# hercules_arm_m3_nvic_trm_r1p1 register map
Vendor: Texas Instruments
Peripheral module from a debugger description file (folder hercules).
Registers are 32-bit, read-write, no defined reset value unless marked. A register's access mark holds for its fields unless they carry their own. Offsets are as the file gives them; lines under a group give offsets from that group; [hi:lo] are bit positions; {n}, {i} and the like mark numbered series; 'fields as' and 'values as' point back to an identical list; <NAME> marks a mode.

## NVIC — Nested Vector Interrupt Controller
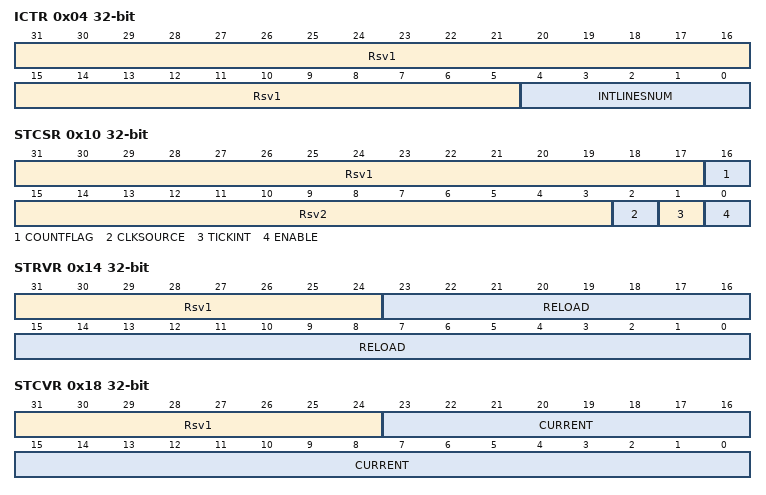
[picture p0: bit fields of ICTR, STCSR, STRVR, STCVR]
0x04 ICTR ro — Interrupt Control Type Register
  [31:5] Rsv1 — Reserved
  [4:0] INTLINESNUM — (N-1)/32 Where N=Number of Interrupt Lines. ex 0=1-32, 1=33-64, etc.
0x10 STCSR access per field — SysTick Control and Status Register
  [31:17] Rsv1 ro — Reserved
  [16] COUNTFLAG rw — Counter Reached 0: 0=No, 1=Yes, Read-Clear
  [15:3] Rsv2 ro — Reserved
  [2] CLKSOURCE rw — Reference Clock Source 0=core clock, 1=external clock
  [1] TICKINT rw — Counter Reaching 0 Pends SysTick Handler 0=No, 1=Yes
  [0] ENABLE rw — Counter Enable: 0=Disabled, 1=Multishot
0x14 STRVR access per field — SysTick Reload Value Register
  [31:24] Rsv1 ro — Reserved
  [23:0] RELOAD rw — Value Loaded by SysTick Counter when Reaching 0
0x18 STCVR access per field — SysTick Current Value Register
  [31:24] Rsv1 ro — Reserved
  [23:0] CURRENT rw — Currrent SysTick Counter Value
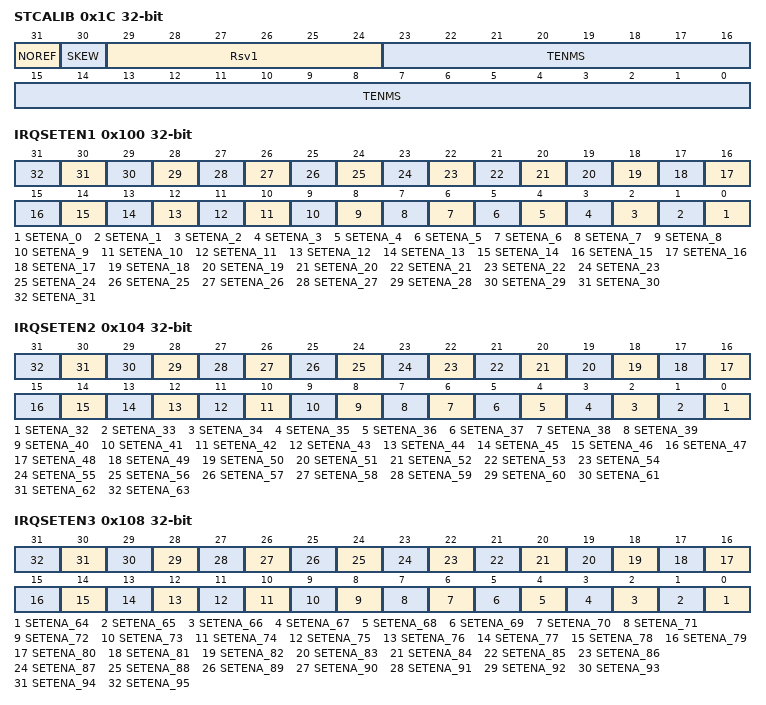
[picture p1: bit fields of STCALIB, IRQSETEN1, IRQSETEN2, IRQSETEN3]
0x1C STCALIB ro — SysTick Calibration Value Register
  [31] NOREF — 1 = Reference Clock Not Provided
  [30] SKEW — 1 = Calibration Value Not Exactly 10ms
  [29:24] Rsv1 — Reserved
  [23:0] TENMS — Reload Value to Generate 10ms SysTick
0x100 IRQSETEN1 — Interrupt 0-31 Set Enable Register
  [n] SETENA_{n} (n=0..31) — Writes: 1 Enables Interrupt, 0 No Effect. Read 1=Interrupt Enabled
0x104 IRQSETEN2 — Interrupt 32-63 Set Enable Register
  [n-32] SETENA_{n} (n=32..63) — Writes: 1 Enables Interrupt, 0 No Effect. Read 1=Interrupt Enabled
0x108 IRQSETEN3 — Interrupt 64-95 Set Enable Register
  [n-64] SETENA_{n} (n=64..95) — Writes: 1 Enables Interrupt, 0 No Effect. Read 1=Interrupt Enabled
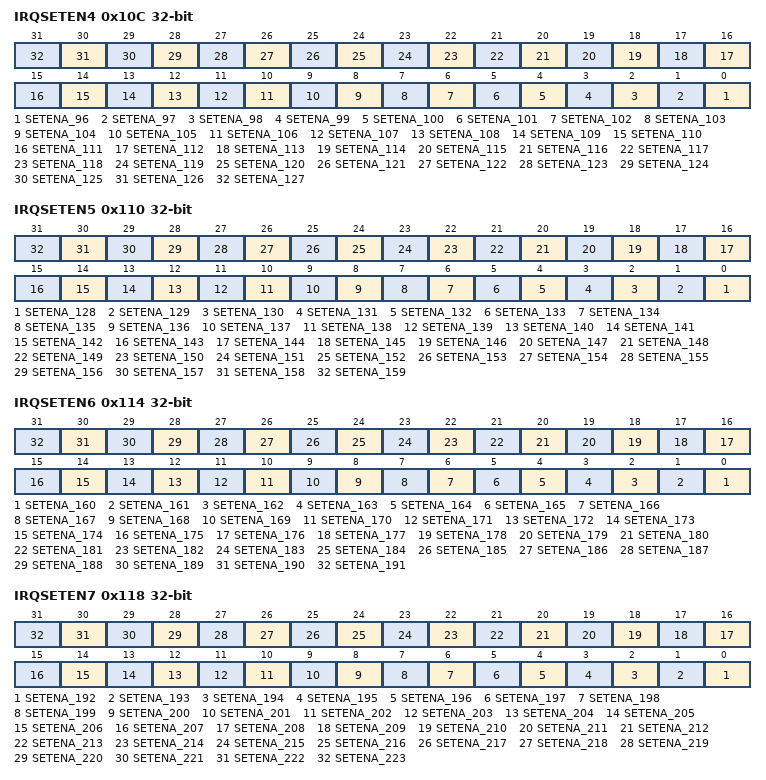
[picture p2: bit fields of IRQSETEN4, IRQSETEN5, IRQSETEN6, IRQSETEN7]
0x10C IRQSETEN4 — Interrupt 96-127 Set Enable Register
  [n-96] SETENA_{n} (n=96..127) — Writes: 1 Enables Interrupt, 0 No Effect. Read 1=Interrupt Enabled
0x110 IRQSETEN5 — Interrupt 128-159 Set Enable Register
  [n-128] SETENA_{n} (n=128..159) — Writes: 1 Enables Interrupt, 0 No Effect. Read 1=Interrupt Enabled
0x114 IRQSETEN6 — Interrupt 160-191 Set Enable Register
  [n-160] SETENA_{n} (n=160..191) — Writes: 1 Enables Interrupt, 0 No Effect. Read 1=Interrupt Enabled
0x118 IRQSETEN7 — Interrupt 192-223 Set Enable Register
  [n-192] SETENA_{n} (n=192..223) — Writes: 1 Enables Interrupt, 0 No Effect. Read 1=Interrupt Enabled
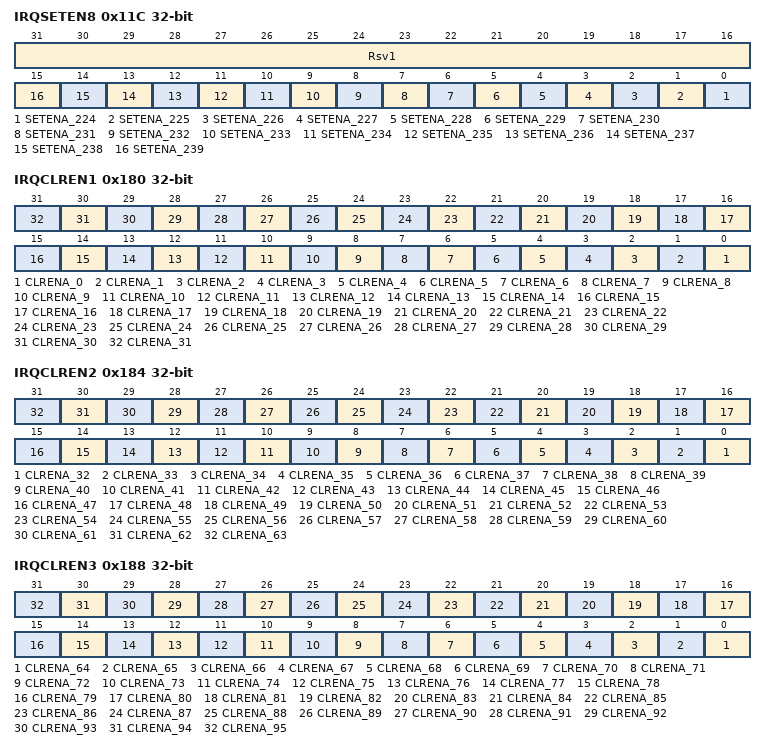
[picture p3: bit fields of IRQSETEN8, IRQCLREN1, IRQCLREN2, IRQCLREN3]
0x11C IRQSETEN8 access per field — Interrupt 224-239 Set Enable Register
  [31:16] Rsv1 ro — Reserved
  [n-224] SETENA_{n} rw (n=224..239) — Writes: 1 Enables Interrupt, 0 No Effect. Read 1=Interrupt Enabled
0x180 IRQCLREN1 — Interrupt 0-31 Clear Enable Register
  [n] CLRENA_{n} (n=0..31) — Writes: 1 Disables Interrupt, 0 No Effect. Read 1=Interrupt Enabled
0x184 IRQCLREN2 — Interrupt 32-63 Clear Enable Register
  [n-32] CLRENA_{n} (n=32..63) — Writes: 1 Disables Interrupt, 0 No Effect. Read 1=Interrupt Enabled
0x188 IRQCLREN3 — Interrupt 64-95 Clear Enable Register
  [n-64] CLRENA_{n} (n=64..95) — Writes: 1 Disables Interrupt, 0 No Effect. Read 1=Interrupt Enabled
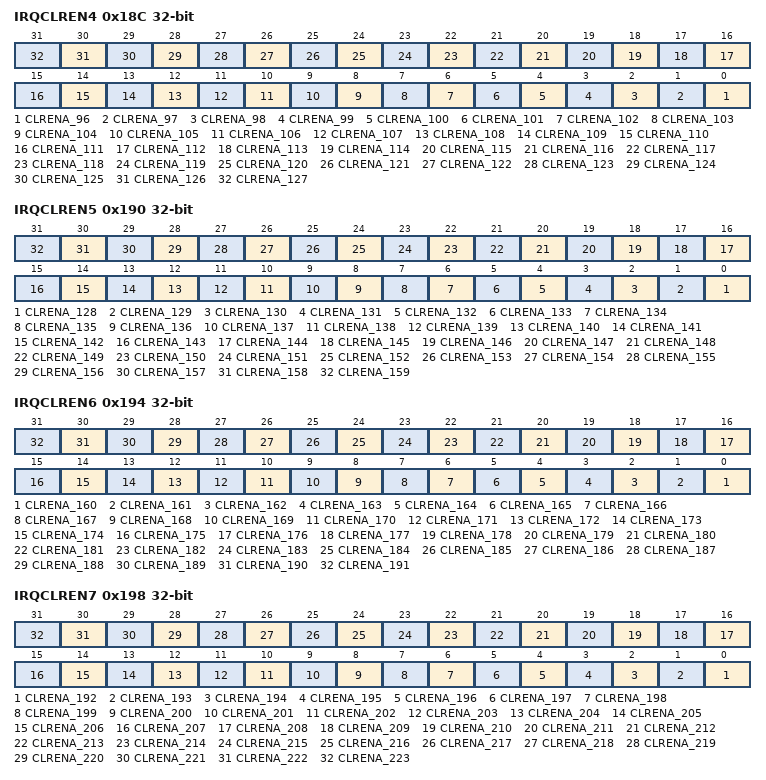
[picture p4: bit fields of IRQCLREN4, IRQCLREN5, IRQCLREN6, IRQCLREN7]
0x18C IRQCLREN4 — Interrupt 96-127 Clear Enable Register
  [n-96] CLRENA_{n} (n=96..127) — Writes: 1 Disables Interrupt, 0 No Effect. Read 1=Interrupt Enabled
0x190 IRQCLREN5 — Interrupt 128-159 Clear Enable Register
  [n-128] CLRENA_{n} (n=128..159) — Writes: 1 Disables Interrupt, 0 No Effect. Read 1=Interrupt Enabled
0x194 IRQCLREN6 — Interrupt 160-191 Clear Enable Register
  [n-160] CLRENA_{n} (n=160..191) — Writes: 1 Disables Interrupt, 0 No Effect. Read 1=Interrupt Enabled
0x198 IRQCLREN7 — Interrupt 192-223 Clear Enable Register
  [n-192] CLRENA_{n} (n=192..223) — Writes: 1 Disables Interrupt, 0 No Effect. Read 1=Interrupt Enabled
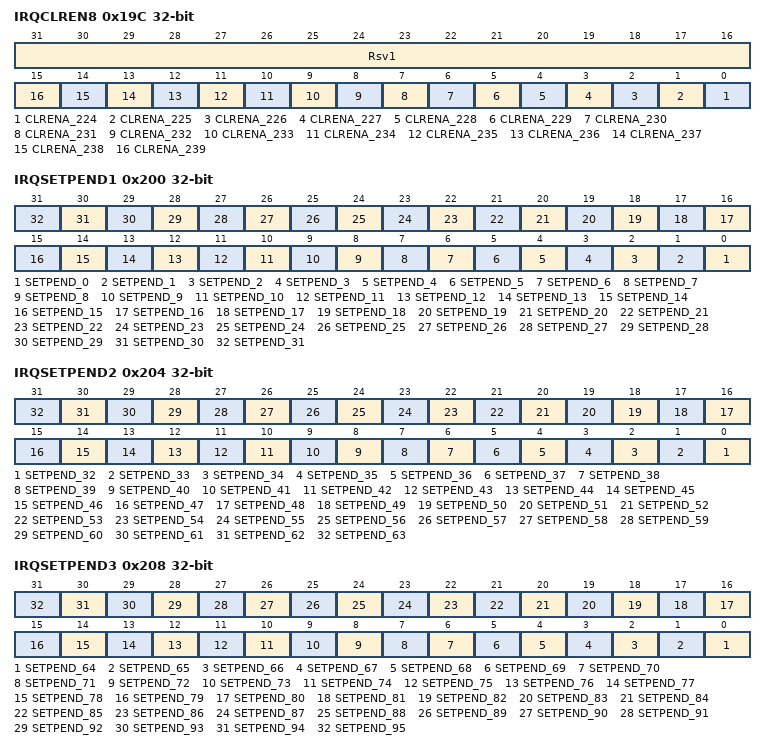
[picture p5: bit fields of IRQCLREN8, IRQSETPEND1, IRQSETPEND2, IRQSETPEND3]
0x19C IRQCLREN8 access per field — Interrupt 224-239 Clear Enable Register
  [31:16] Rsv1 ro — Reserved
  [n-224] CLRENA_{n} rw (n=224..239) — Writes: 1 Disables Interrupt, 0 No Effect. Read 1=Interrupt Enabled
0x200 IRQSETPEND1 — Interrupt 0-31 Set Pending Register
  [n] SETPEND_{n} (n=0..31) — Writes: 1 Pends Interrupt, 0 No Effect. Read 1=Interrupt Pending
0x204 IRQSETPEND2 — Interrupt 32-63 Set Pending Register
  [n-32] SETPEND_{n} (n=32..63) — Writes: 1 Pends Interrupt, 0 No Effect. Read 1=Interrupt Pending
0x208 IRQSETPEND3 — Interrupt 64-95 Set Pending Register
  [n-64] SETPEND_{n} (n=64..95) — Writes: 1 Pends Interrupt, 0 No Effect. Read 1=Interrupt Pending
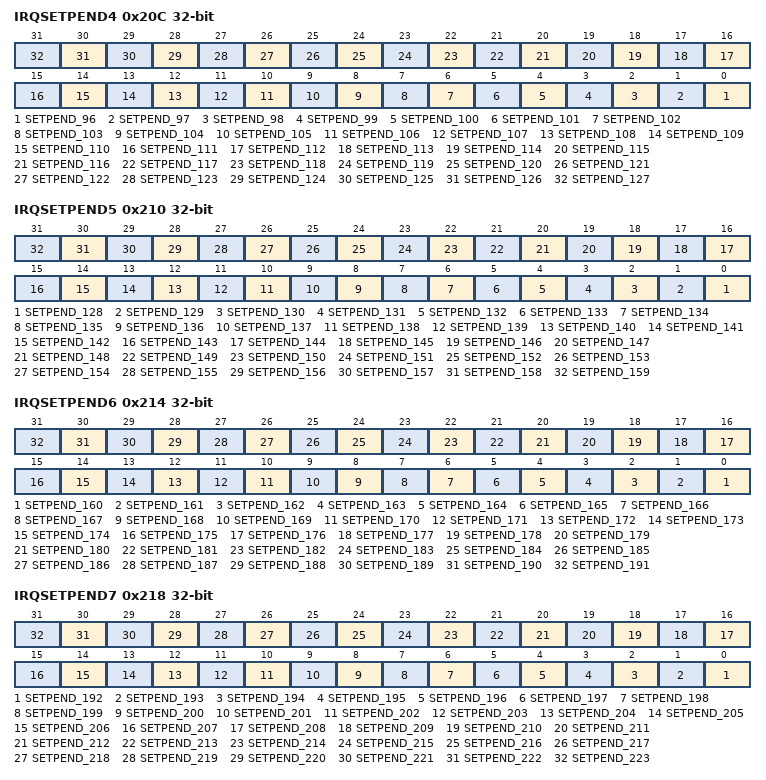
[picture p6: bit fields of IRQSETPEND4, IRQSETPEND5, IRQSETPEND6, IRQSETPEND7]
0x20C IRQSETPEND4 — Interrupt 96-127 Set Pending Register
  [n-96] SETPEND_{n} (n=96..127) — Writes: 1 Pends Interrupt, 0 No Effect. Read 1=Interrupt Pending
0x210 IRQSETPEND5 — Interrupt 128-159 Set Pending Register
  [n-128] SETPEND_{n} (n=128..159) — Writes: 1 Pends Interrupt, 0 No Effect. Read 1=Interrupt Pending
0x214 IRQSETPEND6 — Interrupt 160-191 Set Pending Register
  [n-160] SETPEND_{n} (n=160..191) — Writes: 1 Pends Interrupt, 0 No Effect. Read 1=Interrupt Pending
0x218 IRQSETPEND7 — Interrupt 192-223 Set Pending Register
  [n-192] SETPEND_{n} (n=192..223) — Writes: 1 Pends Interrupt, 0 No Effect. Read 1=Interrupt Pending
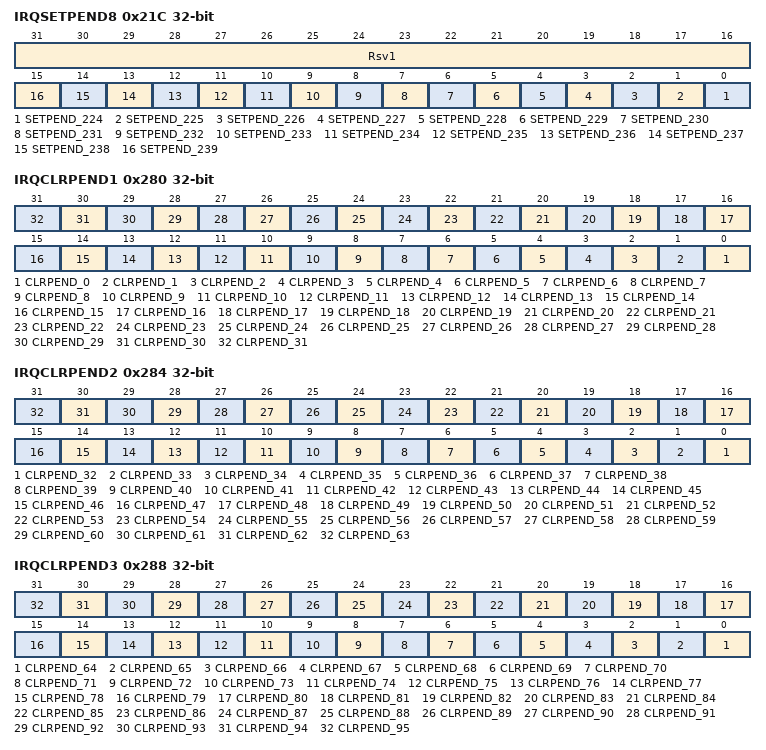
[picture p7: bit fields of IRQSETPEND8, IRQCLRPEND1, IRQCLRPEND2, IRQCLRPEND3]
0x21C IRQSETPEND8 access per field — Interrupt 224-239 Set Pending Register
  [31:16] Rsv1 ro — Reserved
  [n-224] SETPEND_{n} rw (n=224..239) — Writes: 1 Pends Interrupt, 0 No Effect. Read 1=Interrupt Pending
0x280 IRQCLRPEND1 — Interrupt 0-31 Clear Pending Register
  [n] CLRPEND_{n} (n=0..31) — Writes: 1 Clears Pending Interrupt, 0 No Effect. Read 1=Interrupt Pending
0x284 IRQCLRPEND2 — Interrupt 32-63 Clear Pending Register
  [n-32] CLRPEND_{n} (n=32..63) — Writes: 1 Clears Pending Interrupt, 0 No Effect. Read 1=Interrupt Pending
0x288 IRQCLRPEND3 — Interrupt 64-95 Clear Pending Register
  [n-64] CLRPEND_{n} (n=64..95) — Writes: 1 Clears Pending Interrupt, 0 No Effect. Read 1=Interrupt Pending
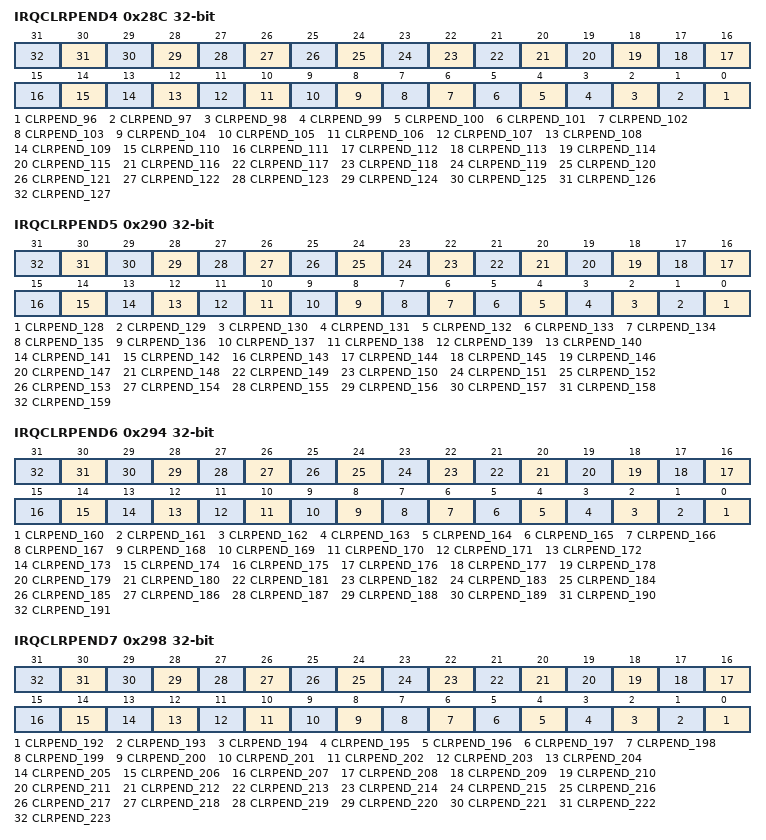
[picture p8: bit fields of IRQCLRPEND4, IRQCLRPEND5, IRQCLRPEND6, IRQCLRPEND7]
0x28C IRQCLRPEND4 — Interrupt 96-127 Clear Pending Register
  [n-96] CLRPEND_{n} (n=96..127) — Writes: 1 Clears Pending Interrupt, 0 No Effect. Read 1=Interrupt Pending
0x290 IRQCLRPEND5 — Interrupt 128-159 Clear Pending Register
  [n-128] CLRPEND_{n} (n=128..159) — Writes: 1 Clears Pending Interrupt, 0 No Effect. Read 1=Interrupt Pending
0x294 IRQCLRPEND6 — Interrupt 160-191 Clear Pending Register
  [n-160] CLRPEND_{n} (n=160..191) — Writes: 1 Clears Pending Interrupt, 0 No Effect. Read 1=Interrupt Pending
0x298 IRQCLRPEND7 — Interrupt 192-223 Clear Pending Register
  [n-192] CLRPEND_{n} (n=192..223) — Writes: 1 Clears Pending Interrupt, 0 No Effect. Read 1=Interrupt Pending
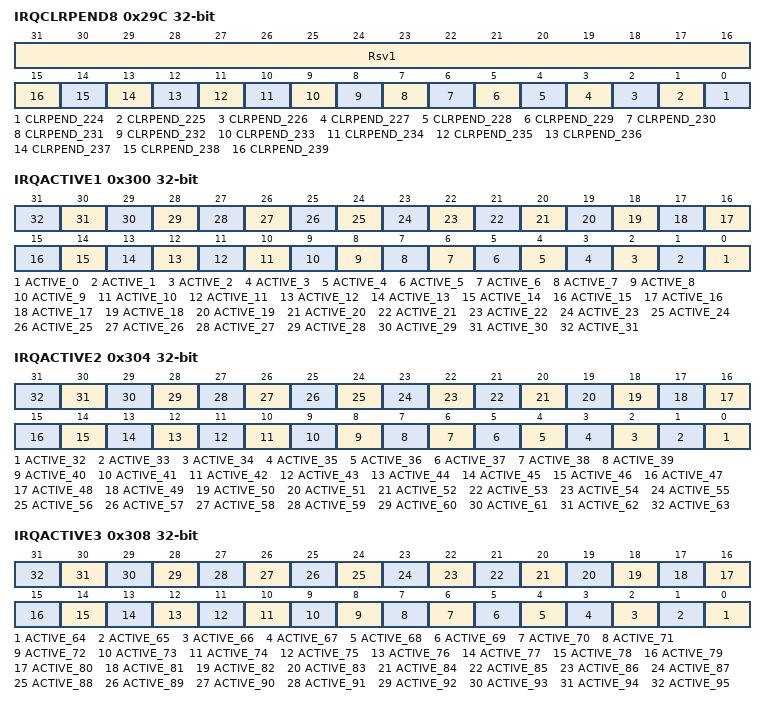
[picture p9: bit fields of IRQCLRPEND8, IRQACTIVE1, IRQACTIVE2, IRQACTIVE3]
0x29C IRQCLRPEND8 access per field — Interrupt 224-239 Clear Pending Register
  [31:16] Rsv1 ro — Reserved
  [n-224] CLRPEND_{n} rw (n=224..239) — Writes: 1 Clears Pending Interrupt, 0 No Effect. Read 1=Interrupt Pending
0x300 IRQACTIVE1 ro — Interrupt 0-31 Active Bit Register
  [n] ACTIVE_{n} (n=0..31) — Read Only 1=Interrupt Active or Pre-Empted 0=Interrupt Inactive
0x304 IRQACTIVE2 ro — Interrupt 32-63 Active Bit Register
  [n-32] ACTIVE_{n} (n=32..63) — Read Only 1=Interrupt Active or Pre-Empted 0=Interrupt Inactive
0x308 IRQACTIVE3 ro — Interrupt 64-95 Active Bit Register
  [n-64] ACTIVE_{n} (n=64..95) — Read Only 1=Interrupt Active or Pre-Empted 0=Interrupt Inactive
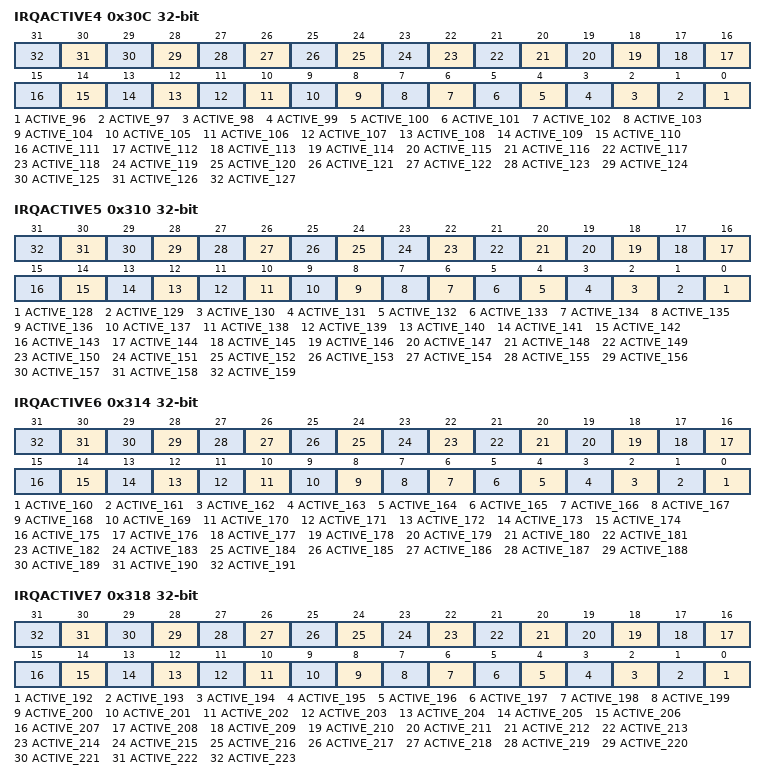
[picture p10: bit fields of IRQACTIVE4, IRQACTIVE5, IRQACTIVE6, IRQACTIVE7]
0x30C IRQACTIVE4 ro — Interrupt 96-127 Active Bit Register
  [n-96] ACTIVE_{n} (n=96..127) — Read Only 1=Interrupt Active or Pre-Empted 0=Interrupt Inactive
0x310 IRQACTIVE5 ro — Interrupt 128-159 Active Bit Register
  [n-128] ACTIVE_{n} (n=128..159) — Read Only 1=Interrupt Active or Pre-Empted 0=Interrupt Inactive
0x314 IRQACTIVE6 ro — Interrupt 160-191 Active Bit Register
  [n-160] ACTIVE_{n} (n=160..191) — Read Only 1=Interrupt Active or Pre-Empted 0=Interrupt Inactive
0x318 IRQACTIVE7 ro — Interrupt 192-223 Active Bit Register
  [n-192] ACTIVE_{n} (n=192..223) — Read Only 1=Interrupt Active or Pre-Empted 0=Interrupt Inactive
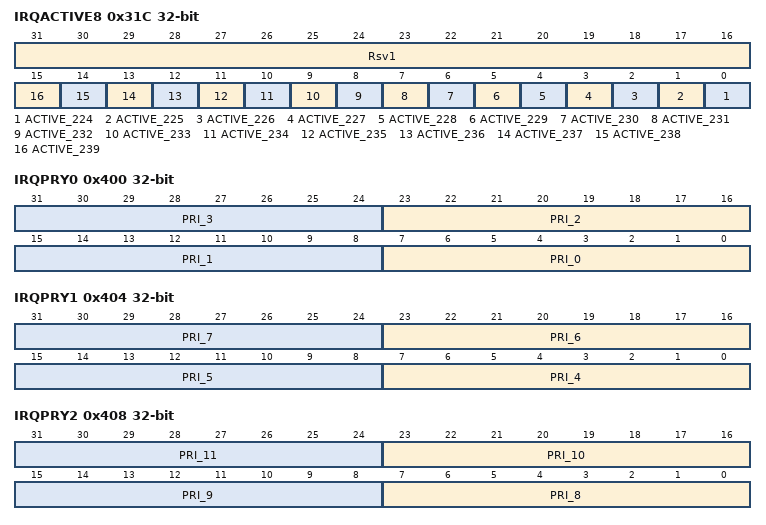
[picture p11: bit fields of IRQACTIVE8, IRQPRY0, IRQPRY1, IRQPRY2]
0x31C IRQACTIVE8 ro — Interrupt 224-239 Active Bit Register
  [31:16] Rsv1 — Reserved
  [n-224] ACTIVE_{n} (n=224..239) — Read Only 1=Interrupt Active or Pre-Empted 0=Interrupt Inactive
0x400 IRQPRY0 — Interrupt 3-0 Priority Register
  [8n+7:8n] PRI_{n} (n=0..3) — Priority of Interrupt {n} 0=Highest,0xFF=Lowest
0x404 IRQPRY1 — Interrupt 7-4 Priority Register
  [8n-25:8n-32] PRI_{n} (n=4..7) — Priority of Interrupt {n} 0=Highest,0xFF=Lowest
0x408 IRQPRY2 — Interrupt 11-8 Priority Register
  [8n-57:8n-64] PRI_{n} (n=8..11) — Priority of Interrupt {n} 0=Highest,0xFF=Lowest
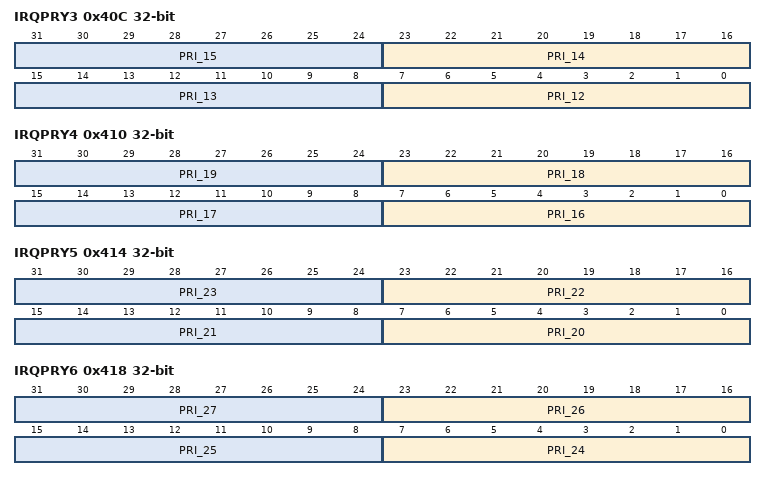
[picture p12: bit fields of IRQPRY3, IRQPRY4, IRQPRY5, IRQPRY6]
0x40C IRQPRY3 — Interrupt 15-12 Priority Register
  [8n-89:8n-96] PRI_{n} (n=12..15) — Priority of Interrupt {n} 0=Highest,0xFF=Lowest
0x410 IRQPRY4 — Interrupt 19-16 Priority Register
  [8n-121:8n-128] PRI_{n} (n=16..19) — Priority of Interrupt {n} 0=Highest,0xFF=Lowest
0x414 IRQPRY5 — Interrupt 23-20 Priority Register
  [8n-153:8n-160] PRI_{n} (n=20..23) — Priority of Interrupt {n} 0=Highest,0xFF=Lowest
0x418 IRQPRY6 — Interrupt 27-24 Priority Register
  [8n-185:8n-192] PRI_{n} (n=24..27) — Priority of Interrupt {n} 0=Highest,0xFF=Lowest
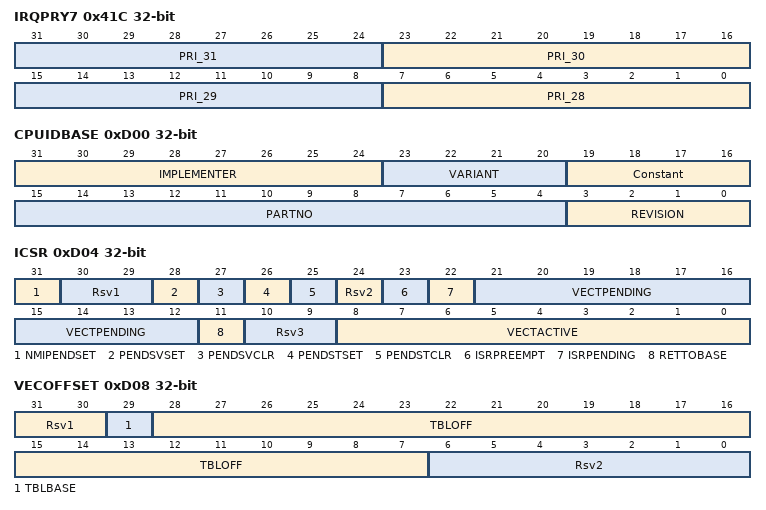
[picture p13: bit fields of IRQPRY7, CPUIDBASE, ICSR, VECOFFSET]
0x41C IRQPRY7 — Interrupt 31-28 Priority Register
  [8n-217:8n-224] PRI_{n} (n=28..31) — Priority of Interrupt {n} 0=Highest,0xFF=Lowest
0xD00 CPUIDBASE ro
  [31:24] IMPLEMENTER — Implementer Code 0x41=ARM
  [23:20] VARIANT — Implementation Defined Variant
  [19:16] Constant — Reads as 0xF
  [15:4] PARTNO — Part Number within Family
  [3:0] REVISION — Implementation Defined Revision Number
0xD04 ICSR access per field — Interrupt Control State Register
  [31] NMIPENDSET rw — Write 1 to Activate NMI
  [30:29] Rsv1 ro — Reserved
  [28] PENDSVSET rw — Write 1 to Set pendSV Bit
  [27] PENDSVCLR rw — Write 1 to Clear pendSV Bit
  [26] PENDSTSET rw — Write 1 to Set pending SysTick
  [25] PENDSTCLR rw — Write 1 to Clear pending SysTick
  [24] Rsv2 ro — Reserved
  [23] ISRPREEMPT ro — Debug Only: Indicates Pending Interrupt Becomes Active During the Next Run Cycle
  [22] ISRPENDING ro — Status 1 = Interrupt Pending (Excluding NMI and Faults)
  [21:12] VECTPENDING ro — Pending ISR Number
  [11] RETTOBASE ro — 1 = Set of all active exceptions except IPSR_current_exception is empty set
  [10:9] Rsv3 ro — Reserved
  [8:0] VECTACTIVE ro — Active ISR Number Field - currently running iSR including NMI and Hard Fault
0xD08 VECOFFSET access per field — Vector Table Offset Register
  [31:30] Rsv1 ro — Reserved
  [29] TBLBASE rw — Table base: 0=Code, 1=RAM
  [28:7] TBLOFF rw — Table base offset from bottom of SRAM or Code Space
  [6:0] Rsv2 ro — Reserved
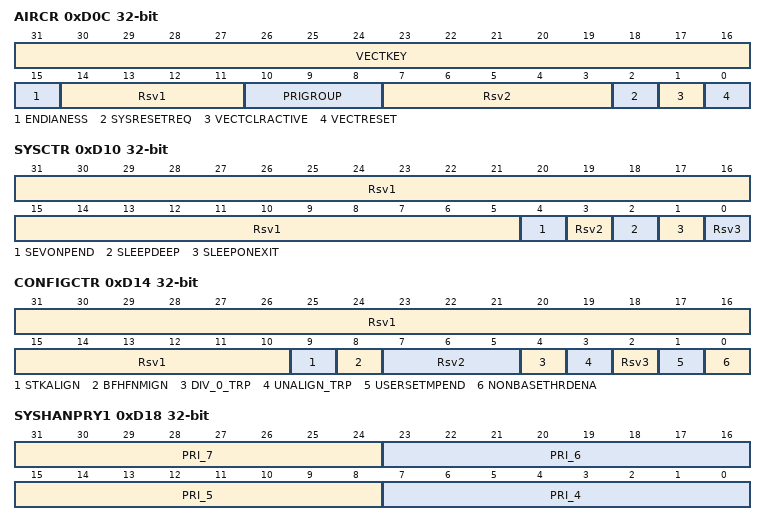
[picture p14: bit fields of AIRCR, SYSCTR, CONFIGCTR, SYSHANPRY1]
0xD0C AIRCR access per field — Application Interrupt and Reset Control Register
  [31:16] VECTKEY rw — Writing requires 0x05FA, reads 0xFA05
  [15] ENDIANESS rw — Data Endian 1=Big, 0=Little
  [14:11] Rsv1 ro — Reserved
  [10:8] PRIGROUP rw — Interrupt Priority Group: 0=7.1, 1=6.2, 2=5.3, ... 7=0.8 pre-emption.sub priority
  [7:3] Rsv2 ro — Reserved
  [2] SYSRESETREQ rw — Assert System Reset Request
  [1] VECTCLRACTIVE rw — Clear Active NMI, fault, Interrupt State
  [0] VECTRESET rw — 1=Reset System
0xD10 SYSCTR access per field — System Control Register
  [31:5] Rsv1 ro — Reserved
  [4] SEVONPEND rw — 1=WFE wakes up on any interrupt pending
  [3] Rsv2 ro — Reserved
  [2] SLEEPDEEP rw — 1=CPU Clock can be stopped
  [1] SLEEPONEXIT rw — 1=Sleep on ISR Exit
  [0] Rsv3 ro — Reserved
0xD14 CONFIGCTR access per field — Configuration Control Register
  [31:10] Rsv1 ro — Reserved
  [9] STKALIGN rw — 1=SP on exception entry is 8 byte aligned
  [8] BFHFNMIGN rw — 1=Priority1,2 handlers ignore data bus fault from load/store
  [7:5] Rsv2 ro — Reserved
  [4] DIV_0_TRP rw — 1=Trap on Divide by Zero
  [3] UNALIGN_TRP rw — 1=Trap on unaligned access
  [2] Rsv3 ro — Reserved
  [1] USERSETMPEND rw — 1=Enables triggering main exception from User Mode
  [0] NONBASETHRDENA rw — 0=Thread mode entry only by returning from last exception
0xD18 SYSHANPRY1 — System Handler 4-7 Priority Register
  [31:24] PRI_7 — Priority of System Handler 7 - Reserved
  [23:16] PRI_6 — Priority of System Handler 6 - Usage Fault
  [15:8] PRI_5 — Priority of System Handler 5 - Bus Fault
  [7:0] PRI_4 — Priority of System Handler 4 - Memory Management
0xD1C SYSHANPRY2 — System Handler 8-11 Priority Register
  [31:24] PRI_11 — Priority of System Handler 11 - SVCall
  [23:16] PRI_10 — Priority of System Handler 10 - reserved
  [15:8] PRI_9 — Priority of System Handler 9 - reserved
  [7:0] PRI_8 — Priority of System Handler 8 - reserved
0xD20 SYSHANPRY3 — System Handler 12-15 Priority Register
  [31:24] PRI_15 — Priority of System Handler 15 - SysTick
  [23:16] PRI_14 — Priority of System Handler 14 - PendSV
  [15:8] PRI_13 — Priority of System Handler 13 - Reserved
  [7:0] PRI_12 — Priority of System Handler 12 - Debug Monitor
0xD24 SYSHANCTRL access per field — System Handler Control and State Register
  [31:19] Rsv1 ro — Reserved
  [18] USGFAULTENA rw — 0=Disable, 1=Enable Usage Fault
  [17] BUSFAULTENA rw — 0=Disable, 1=Enable BusFault
  [16] MEMFAULTENA rw — 0=Disable, 1=Enable MemManage
  [15] SVCALLPENDED rw — Reads 1 if SVCall is Pended
  [14] BUSFAULTPENDED rw — Reads 1 if BusFault is Pended
  [13] MEMFAULTPENDED rw — Reads 1 if MemManage is Pended
  [12] USGFAULTPENDED rw — Reads 1 if Usage Fault is Pendedv
  [11] SYSTICKACT rw — Reads 1 if SysTick is active
  [10] PENDSVACT rw — Reads 1 if PendSV is Active
  [9] Rsv2 ro — Reserved
  [8] MONITORACT rw — Reads 1 if Monitor is Active
  [7] SVCALLACT rw — Reads 1 if SVCall is Active
  [6:4] Rsv3 ro — Reserved
  [3] USGFAULTACT rw — Reads 1 if Usage Fault is Active
  [2] Rsv4 ro — Reserved
  [1] BUSFAULTACT rw — Reads 1 if BusFault is Active
  [0] MEMFAULTACT rw — Reads 1 if MemManage is Active
0xD28 CONFLTSR access per field — Configurable Fault Status Register
  [31:26] Rsv1 ro — Reserved
  [25] DIVBYZERO rw — 1=Divide By Zero Trap Caused Usage Fault
  [24] UNALIGNED rw — 1=Unaligned Trap Caused Usage Fault
  [23:20] Rsv2 ro — Reserved
  [19] NOCP rw — 1=Invalid Coprocessor Access Caused Usage Fault
  [18] INVPC rw — 1=Attempt to load EXC_RETURN into PC illegally caused Usage Fault
  [17] INVSTATE rw — 1=Invalid Combination of EPSR and Instruction Caused Usage Fault
  [16] UNDEFINSTR rw — 1=Undefined Instruction Caused Usage Fault
  [15] BFARVALID rw — 1=Valid Address in BFAR Register
  [14:13] Rsv3 ro — Reserved
  [12] STKERR rw — 1=Stacking from Exception Caused Bus Fault
  [11] UNSTKERR rw — 1=Unstacking from Exception Caused Bus Fault
  [10] IMPRECISERR rw — 1=Imprecise Data Bus Error - Return Address Not Related to Fault
  [9] PRECISERR rw — 1=Precise Data Bus Error - Return Address Caused Fault
  [8] IBUSERR rw — 1=Instruction Bus Error
  [7] MMARVALID rw — 1=Valid Fault Address in MMAR R/W12C
  [6:5] Rsv4 ro — Reserved
  [4] MSTKERR rw — 1=Stacking from Exception Caused Access Violation R/W12C
  [3] MUNSTKERR rw — 1=UnStacking from Exception Caused Access Violation R/W12C
  [2] Rsv5 ro — Reserved
  [1] DACCVIOL rw — 1=Data Access Violation R/W12C
  [0] IACCVIOL rw — 1=Instruction Access Violation R/W12C
0xD2C HRDFLTSR access per field — Hard Fault Status Register
  [31] DEBUGEVT rw — 1=Fault Related to Debug Occurred
  [30] FORCED rw — 1=Hard Fault Activated because Configurable Fault Received but Cannot Activate
  [29:2] Rsv1 ro — Reserved
  [1] VECTTBL rw — 1=Fault During Vector Table Read
  [0] Rsv2 ro — Reserved
0xD30 DBGFLTSR access per field — Debug Fault Status Register
  [31:5] Rsv1 ro — Reserved
  [4] EXTERNAL rw — 1=External Debug Request Asserted EDBGRQ Signal
  [3] VCATCH rw — 1=Vector Catch Occurred
  [2] DWTTRAP rw — 1=Data Watchpoint and Trace Match Occurred
  [1] BKPT rw — 1=BKPT instruction Executed
  [0] HALTED rw — 1=Halt Requested by NVIC - including step
0xD34 MEMMANADR — Memory Manage Fault Address Register
  [31:0] ADDRESS — ADDRESS is the data address of the faulted load/store
0xD38 BUSFLTADR — Bus Fault Address Register
  fields as MEMMANADR
0xD3C AUXFLTSR — Auxilliary Fault Status Register
  [31:0] IMPDEF — Implementation Defined Fault Status Bits
0xD40 PFR0 access not given — Processor Feature Register 0
0xD44 PFR1 access not given — Processor Feature Register 1
0xD48 DBGFR0 access not given — Debug Feature Register 0
0xD4C AUXFR0 access not given — Auxilliary Feature Register 0
{0xD50+4i} MMFR{i} access not given (i=0..3) — Memory Feature Register {i}
{0xD60+4i} ISAR{i} access not given (i=0..3) — ISA Feature Register {i}
0xD70 ISAR4 access not given — ISA Feature Register 7
0xF00 SWTRIGINT access per field — Software Trigger Interrupt Register
  [31:9] Rsv1 ro — Reserved
  [8:0] INTID rw — Writing Interrupt ID is the same as Manually Pending an Interrupt
{0xFC0+4i} PID{i} access not given (i=4..7) — Peripheral Identification Register {i}
{0xFE0+4i} PID{i} access not given (i=0..3) — Peripheral Identification Register {i}
{0xFF0+4i} CID{i} access not given (i=0..3) — Component Identification Register {i}

## Notices in the file
(c) Texas Instruments 2003-2014, All rights reserved.
